VERSION ""

NS_ :

BS_:

BU_: Abgasnachbehandlung Invertersteuerung Kraftstoffsystem Motorsteuerung System

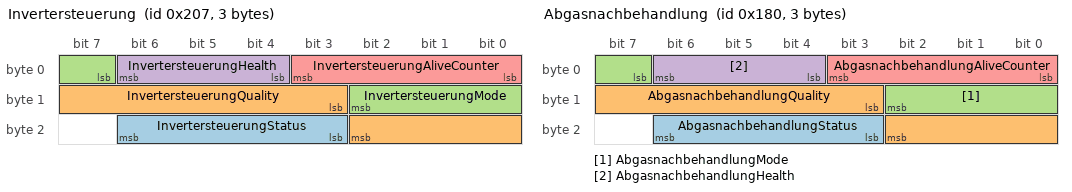
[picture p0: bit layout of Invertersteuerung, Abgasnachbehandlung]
BO_ 519 Invertersteuerung: 3 Invertersteuerung
 SG_ InvertersteuerungStatus : 19|4@1+ (1,0) [0.0|15.0] "code"  System
 SG_ InvertersteuerungQuality : 11|8@1+ (0.5,0.0) [0.0|100.0] "%"  System
 SG_ InvertersteuerungMode : 7|4@1+ (1,0) [0.0|15.0] "code"  System
 SG_ InvertersteuerungHealth : 4|3@1+ (1,0) [0.0|7.0] "code"  System
 SG_ InvertersteuerungAliveCounter : 0|4@1+ (1,0) [0.0|15.0] "count"  System

BO_ 384 Abgasnachbehandlung: 3 Abgasnachbehandlung
 SG_ AbgasnachbehandlungStatus : 19|4@1+ (1,0) [0.0|15.0] "code"  Motorsteuerung,System
 SG_ AbgasnachbehandlungQuality : 11|8@1+ (0.5,0.0) [0.0|100.0] "%"  Motorsteuerung,System
 SG_ AbgasnachbehandlungMode : 7|4@1+ (1,0) [0.0|15.0] "code"  Motorsteuerung,System
 SG_ AbgasnachbehandlungHealth : 4|3@1+ (1,0) [0.0|7.0] "code"  Motorsteuerung,System
 SG_ AbgasnachbehandlungAliveCounter : 0|4@1+ (1,0) [0.0|15.0] "count"  Motorsteuerung,System

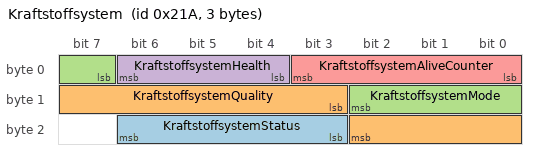
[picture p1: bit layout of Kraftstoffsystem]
BO_ 538 Kraftstoffsystem: 3 Kraftstoffsystem
 SG_ KraftstoffsystemStatus : 19|4@1+ (1,0) [0.0|15.0] "code"  System
 SG_ KraftstoffsystemQuality : 11|8@1+ (0.5,0.0) [0.0|100.0] "%"  System
 SG_ KraftstoffsystemMode : 7|4@1+ (1,0) [0.0|15.0] "code"  System
 SG_ KraftstoffsystemHealth : 4|3@1+ (1,0) [0.0|7.0] "code"  System
 SG_ KraftstoffsystemAliveCounter : 0|4@1+ (1,0) [0.0|15.0] "count"  System

CM_ BO_ 519 "CanonicalMessage=38c83b32-ce91-4237-a3de-01cccd232d55; Network=Antriebsstrang_01-S01-CAP-S02; Technology=can_fd";
CM_ SG_ 519 InvertersteuerungStatus "CanonicalSignal=fb549625-f6f1-40df-9709-ba9e752fd559";
CM_ SG_ 519 InvertersteuerungQuality "CanonicalSignal=21ad87e4-b89d-4960-b413-6bc6c9a24d47";
CM_ SG_ 519 InvertersteuerungMode "CanonicalSignal=4b77d697-473a-4752-b558-88801882dbf1";
CM_ SG_ 519 InvertersteuerungHealth "CanonicalSignal=acbf9819-ffae-4556-a8be-22e410ae4a96";
CM_ SG_ 519 InvertersteuerungAliveCounter "CanonicalSignal=02c7437d-f7b4-4673-a43a-744cbebd14e6";
CM_ BO_ 384 "CanonicalMessage=261ddd50-8909-41bc-982e-66ade7ad4d1d; Network=Antriebsstrang_01-S01-CAP-S02; Technology=can_fd";
CM_ SG_ 384 AbgasnachbehandlungStatus "CanonicalSignal=a3340e98-3748-43db-893e-29f0fe5c0be9";
CM_ SG_ 384 AbgasnachbehandlungQuality "CanonicalSignal=5d6e4645-318d-49d4-9807-480331ea0581";
CM_ SG_ 384 AbgasnachbehandlungMode "CanonicalSignal=2144d30b-47e0-4eb4-a323-c43cd5d33309";
CM_ SG_ 384 AbgasnachbehandlungHealth "CanonicalSignal=57bbe956-020b-4af6-a7cc-a228abb03ef8";
CM_ SG_ 384 AbgasnachbehandlungAliveCounter "CanonicalSignal=b1d77248-d1c0-4161-a944-ff3642882e72";
CM_ BO_ 538 "CanonicalMessage=941dfce3-bbce-46cf-9f75-5168a2ecb4fa; Network=Antriebsstrang_01-S01-CAP-S02; Technology=can_fd";
CM_ SG_ 538 KraftstoffsystemStatus "CanonicalSignal=66712c12-235b-43f2-a014-f0139a5dd36d";
CM_ SG_ 538 KraftstoffsystemQuality "CanonicalSignal=8d4731ca-92b7-40c6-9e9b-2434d0c33534";
CM_ SG_ 538 KraftstoffsystemMode "CanonicalSignal=a61c4d08-111d-4d4c-b217-7d058fefafb1";
CM_ SG_ 538 KraftstoffsystemHealth "CanonicalSignal=689afef1-9cae-4ef7-96d2-12831ddd6433";
CM_ SG_ 538 KraftstoffsystemAliveCounter "CanonicalSignal=a78d462c-1bd8-4c77-be38-67866bf1c802";
BA_DEF_ BO_  "VFrameFormat" ENUM  "StandardCAN","ExtendedCAN","StandardCAN_FD","ExtendedCAN_FD";
BA_DEF_DEF_  "VFrameFormat" "0";
BA_ "VFrameFormat" BO_ 519 2;
BA_ "VFrameFormat" BO_ 384 2;
BA_ "VFrameFormat" BO_ 538 2;
